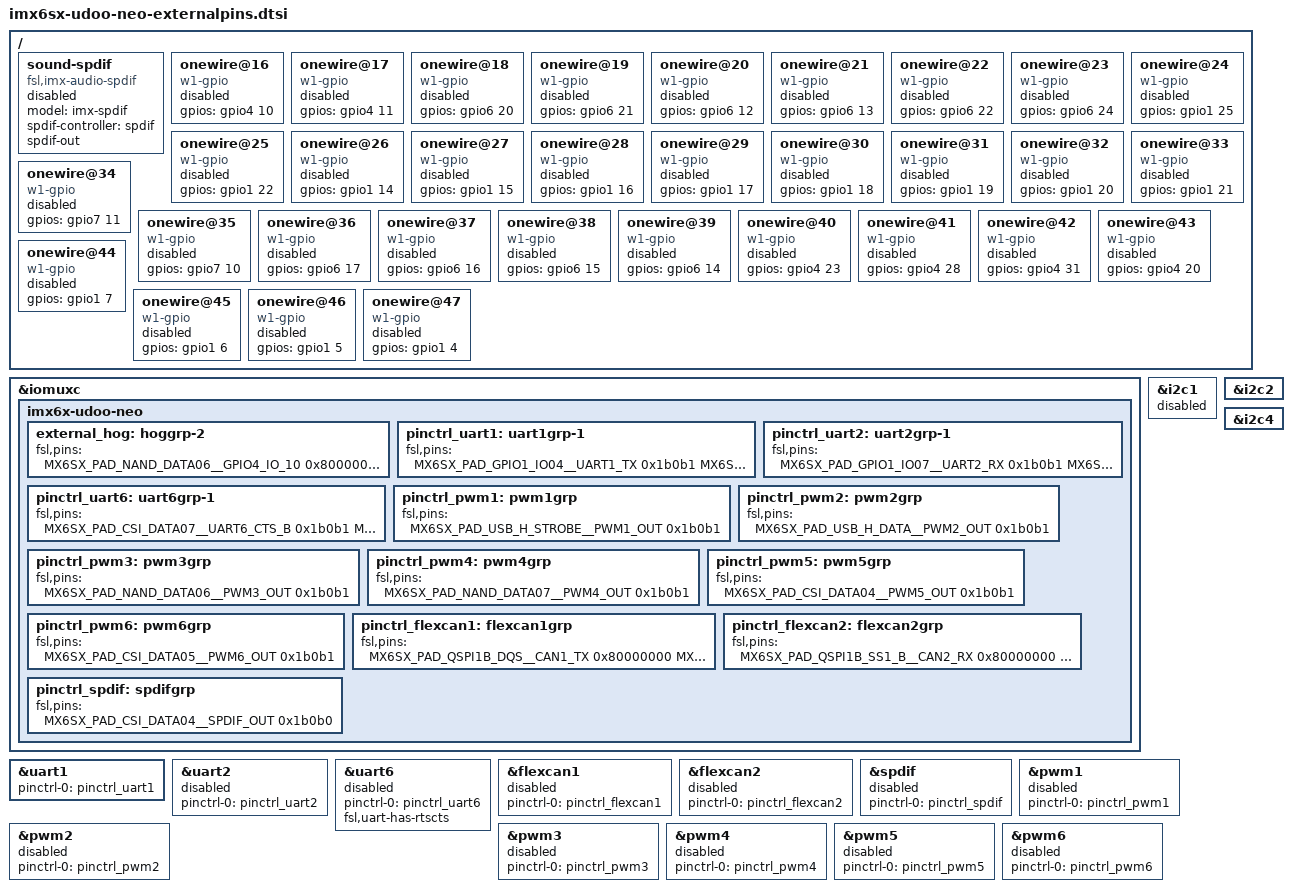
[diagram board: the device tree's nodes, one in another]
/*
 * Author: Francesco Montefoschi <francesco.monte@gmail.com> 
 *
 * This program is free software; you can redistribute it and/or modify
 * it under the terms of the GNU General Public License version 2 as
 * published by the Free Software Foundation.
 *
 */
 

&iomuxc {
    imx6x-udoo-neo {
        // External Pinout GPIOs
        external_hog: hoggrp-2 {
			fsl,pins = <
				MX6SX_PAD_NAND_DATA06__GPIO4_IO_10		0x80000000	// {{external-gpio-16}}
				MX6SX_PAD_NAND_DATA07__GPIO4_IO_11		0x80000000	// {{external-gpio-17}}
				MX6SX_PAD_SD4_DATA6__GPIO6_IO_20		0x80000000	// {{external-gpio-18}}
				MX6SX_PAD_SD4_DATA7__GPIO6_IO_21		0x80000000	// {{external-gpio-19}}
				MX6SX_PAD_SD4_CLK__GPIO6_IO_12			0x80000000	// {{external-gpio-20}}
				MX6SX_PAD_SD4_CMD__GPIO6_IO_13			0x80000000	// {{external-gpio-21}}
				MX6SX_PAD_SD4_RESET_B__GPIO6_IO_22		0x80000000	// {{external-gpio-22}}
				MX6SX_PAD_CSI_PIXCLK__GPIO1_IO_24		0x80000000	// {{external-gpio-23}}	
						
				MX6SX_PAD_CSI_VSYNC__GPIO1_IO_25		0x80000000	// {{external-gpio-24}}
				MX6SX_PAD_CSI_HSYNC__GPIO1_IO_22		0x80000000	// {{external-gpio-25}}
				MX6SX_PAD_CSI_DATA00__GPIO1_IO_14		0x80000000	// {{external-gpio-26}}
				MX6SX_PAD_CSI_DATA01__GPIO1_IO_15		0x80000000	// {{external-gpio-27}}
				MX6SX_PAD_CSI_DATA02__GPIO1_IO_16		0x80000000	// {{external-gpio-28}}
				MX6SX_PAD_CSI_DATA03__GPIO1_IO_17		0x80000000	// {{external-gpio-29}}
				MX6SX_PAD_CSI_DATA04__GPIO1_IO_18		0x80000000	// {{external-gpio-30}}
				MX6SX_PAD_CSI_DATA05__GPIO1_IO_19		0x80000000	// {{external-gpio-31}}
				MX6SX_PAD_CSI_DATA06__GPIO1_IO_20		0x80000000	// {{external-gpio-32}}
				MX6SX_PAD_CSI_DATA07__GPIO1_IO_21		0x80000000	// {{external-gpio-33}}
				
				MX6SX_PAD_USB_H_STROBE__GPIO7_IO_11		0x80000000	// {{external-gpio-34}}
				MX6SX_PAD_USB_H_DATA__GPIO7_IO_10		0x80000000	// {{external-gpio-35}}
				MX6SX_PAD_SD4_DATA3__GPIO6_IO_17		0x80000000	// {{external-gpio-36}}
				MX6SX_PAD_SD4_DATA2__GPIO6_IO_16		0x80000000	// {{external-gpio-37}}
				MX6SX_PAD_SD4_DATA1__GPIO6_IO_15		0x80000000	// {{external-gpio-38}}
				MX6SX_PAD_SD4_DATA0__GPIO6_IO_14		0x80000000	// {{external-gpio-39}}
				
				MX6SX_PAD_QSPI1A_SS1_B__GPIO4_IO_23		0x80000000	// {{external-gpio-40}}
				MX6SX_PAD_QSPI1B_DQS__GPIO4_IO_28		0x80000000	// {{external-gpio-41}}
				MX6SX_PAD_QSPI1B_SS1_B__GPIO4_IO_31		0x80000000	// {{external-gpio-42}}
				MX6SX_PAD_QSPI1A_DQS__GPIO4_IO_20		0x80000000	// {{external-gpio-43}}
				MX6SX_PAD_GPIO1_IO07__GPIO1_IO_7		0x80000000	// {{external-gpio-44}}
				MX6SX_PAD_GPIO1_IO06__GPIO1_IO_6		0x80000000	// {{external-gpio-45}}
				MX6SX_PAD_GPIO1_IO05__GPIO1_IO_5		0x80000000	// {{external-gpio-46}}
				MX6SX_PAD_GPIO1_IO04__GPIO1_IO_4		0x80000000	// {{external-gpio-47}}
			>;
		};
	
		pinctrl_uart1: uart1grp-1 {
			fsl,pins = <
				MX6SX_PAD_GPIO1_IO04__UART1_TX          0x1b0b1
				MX6SX_PAD_GPIO1_IO05__UART1_RX          0x1b0b1
			>;
		};

		pinctrl_uart2: uart2grp-1 {
			fsl,pins = <
				MX6SX_PAD_GPIO1_IO07__UART2_RX          0x1b0b1
				MX6SX_PAD_GPIO1_IO06__UART2_TX          0x1b0b1
			>;
		};

		pinctrl_uart6: uart6grp-1 {
			fsl,pins = <
				MX6SX_PAD_CSI_DATA07__UART6_CTS_B       0x1b0b1
				MX6SX_PAD_CSI_DATA06__UART6_RTS_B       0x1b0b1
				MX6SX_PAD_CSI_DATA05__UART6_TX          0x1b0b1
				MX6SX_PAD_CSI_DATA04__UART6_RX          0x1b0b1
			>;
		};

		pinctrl_pwm1: pwm1grp {
			fsl,pins = <
				MX6SX_PAD_USB_H_STROBE__PWM1_OUT	0x1b0b1
			>;
		};
		
		pinctrl_pwm2: pwm2grp {
			fsl,pins = <
				MX6SX_PAD_USB_H_DATA__PWM2_OUT	0x1b0b1
			>;
		};
		
		pinctrl_pwm3: pwm3grp {
			fsl,pins = <
				MX6SX_PAD_NAND_DATA06__PWM3_OUT	0x1b0b1
			>;
		};
		
		pinctrl_pwm4: pwm4grp {
			fsl,pins = <
				MX6SX_PAD_NAND_DATA07__PWM4_OUT	0x1b0b1
			>;
		};

		pinctrl_pwm5: pwm5grp {
			fsl,pins = <
				MX6SX_PAD_CSI_DATA04__PWM5_OUT	0x1b0b1
			>;
		};

		pinctrl_pwm6: pwm6grp {
			fsl,pins = <
				MX6SX_PAD_CSI_DATA05__PWM6_OUT	0x1b0b1
			>;
		};

		pinctrl_flexcan1: flexcan1grp {
			fsl,pins = <
				MX6SX_PAD_QSPI1B_DQS__CAN1_TX		0x80000000
				MX6SX_PAD_QSPI1A_SS1_B__CAN1_RX		0x80000000
			>;
		};

		pinctrl_flexcan2: flexcan2grp {
			fsl,pins = <
				MX6SX_PAD_QSPI1B_SS1_B__CAN2_RX		0x80000000
				MX6SX_PAD_QSPI1A_DQS__CAN2_TX		0x80000000
			>;
		};

		pinctrl_spdif: spdifgrp {
			fsl,pins = <
				MX6SX_PAD_CSI_DATA04__SPDIF_OUT		0x1b0b0
			>;
		};
	};
 };

&uart1 {
	pinctrl-names = "default";
	pinctrl-0 = <&pinctrl_uart1>;
	status = "okay";
};

&uart2 {
	pinctrl-names = "default";
	pinctrl-0 = <&pinctrl_uart2>;
	status = "disabled";
};

&uart6 {
	pinctrl-names = "default";
	pinctrl-0 = <&pinctrl_uart6>;
	fsl,uart-has-rtscts;
	status = "disabled";
};

&i2c1 {
	status = "disabled";
};

&i2c2 {
	status = "okay";
};

&i2c4 {
	status = "okay";
};

&flexcan1 {
	pinctrl-names = "default";
	pinctrl-0 = <&pinctrl_flexcan1>;
	status = "disabled";
};

&flexcan2 {
	pinctrl-names = "default";
	pinctrl-0 = <&pinctrl_flexcan2>;
	status = "disabled";
};

&spdif {
   pinctrl-names = "default";
   pinctrl-0 = <&pinctrl_spdif>;
   status = "disabled";
};

&pwm1 {
    pinctrl-names = "default";
    pinctrl-0 = <&pinctrl_pwm1>;
    status = "disabled";
};

&pwm2 {
    pinctrl-names = "default";
    pinctrl-0 = <&pinctrl_pwm2>;
    status = "disabled";
};

&pwm3 {
    pinctrl-names = "default";
    pinctrl-0 = <&pinctrl_pwm3>;
    status = "disabled";
};

&pwm4 {
    pinctrl-names = "default";
    pinctrl-0 = <&pinctrl_pwm4>;
    status = "disabled";
};

&pwm5 {
    pinctrl-names = "default";
    pinctrl-0 = <&pinctrl_pwm5>;
    status = "disabled";
};

&pwm6 {
    pinctrl-names = "default";
    pinctrl-0 = <&pinctrl_pwm6>;
    status = "disabled";
};

/ {
	sound-spdif {
		compatible = "fsl,imx-audio-spdif";
		model = "imx-spdif";
		spdif-controller = <&spdif>;
		spdif-out;
		status = "disabled";
	};

	onewire@16 {
		compatible = "w1-gpio";
		gpios = <&gpio4 10 GPIO_ACTIVE_HIGH>;
		status = "disabled";
	};

	onewire@17 {
		compatible = "w1-gpio";
		gpios = <&gpio4 11 GPIO_ACTIVE_HIGH>;
		status = "disabled";
	};

	onewire@18 {
		compatible = "w1-gpio";
		gpios = <&gpio6 20 GPIO_ACTIVE_HIGH>;
		status = "disabled";
	};

	onewire@19 {
		compatible = "w1-gpio";
		gpios = <&gpio6 21 GPIO_ACTIVE_HIGH>;
		status = "disabled";
	};

	onewire@20 {
		compatible = "w1-gpio";
		gpios = <&gpio6 12 GPIO_ACTIVE_HIGH>;
		status = "disabled";
	};

	onewire@21 {
		compatible = "w1-gpio";
		gpios = <&gpio6 13 GPIO_ACTIVE_HIGH>;
		status = "disabled";
	};

	onewire@22 {
		compatible = "w1-gpio";
		gpios = <&gpio6 22 GPIO_ACTIVE_HIGH>;
		status = "disabled";
	};

	onewire@23 {
		compatible = "w1-gpio";
		gpios = <&gpio6 24 GPIO_ACTIVE_HIGH>;
		status = "disabled";
	};

	onewire@24 {
		compatible = "w1-gpio";
		gpios = <&gpio1 25 GPIO_ACTIVE_HIGH>;
		status = "disabled";
	};

	onewire@25 {
		compatible = "w1-gpio";
		gpios = <&gpio1 22 GPIO_ACTIVE_HIGH>;
		status = "disabled";
	};

	onewire@26 {
		compatible = "w1-gpio";
		gpios = <&gpio1 14 GPIO_ACTIVE_HIGH>;
		status = "disabled";
	};

	onewire@27 {
		compatible = "w1-gpio";
		gpios = <&gpio1 15 GPIO_ACTIVE_HIGH>;
		status = "disabled";
	};

	onewire@28 {
		compatible = "w1-gpio";
		gpios = <&gpio1 16 GPIO_ACTIVE_HIGH>;
		status = "disabled";
	};

	onewire@29 {
		compatible = "w1-gpio";
		gpios = <&gpio1 17 GPIO_ACTIVE_HIGH>;
		status = "disabled";
	};

	onewire@30 {
		compatible = "w1-gpio";
		gpios = <&gpio1 18 GPIO_ACTIVE_HIGH>;
		status = "disabled";
	};

	onewire@31 {
		compatible = "w1-gpio";
		gpios = <&gpio1 19 GPIO_ACTIVE_HIGH>;
		status = "disabled";
	};

	onewire@32 {
		compatible = "w1-gpio";
		gpios = <&gpio1 20 GPIO_ACTIVE_HIGH>;
		status = "disabled";
	};

	onewire@33 {
		compatible = "w1-gpio";
		gpios = <&gpio1 21 GPIO_ACTIVE_HIGH>;
		status = "disabled";
	};

	onewire@34 {
		compatible = "w1-gpio";
		gpios = <&gpio7 11 GPIO_ACTIVE_HIGH>;
		status = "disabled";
	};

	onewire@35 {
		compatible = "w1-gpio";
		gpios = <&gpio7 10 GPIO_ACTIVE_HIGH>;
		status = "disabled";
	};

	onewire@36 {
		compatible = "w1-gpio";
		gpios = <&gpio6 17 GPIO_ACTIVE_HIGH>;
		status = "disabled";
	};

	onewire@37 {
		compatible = "w1-gpio";
		gpios = <&gpio6 16 GPIO_ACTIVE_HIGH>;
		status = "disabled";
	};

	onewire@38 {
		compatible = "w1-gpio";
		gpios = <&gpio6 15 GPIO_ACTIVE_HIGH>;
		status = "disabled";
	};

	onewire@39 {
		compatible = "w1-gpio";
		gpios = <&gpio6 14 GPIO_ACTIVE_HIGH>;
		status = "disabled";
	};

	onewire@40 {
		compatible = "w1-gpio";
		gpios = <&gpio4 23 GPIO_ACTIVE_HIGH>;
		status = "disabled";
	};

	onewire@41 {
		compatible = "w1-gpio";
		gpios = <&gpio4 28 GPIO_ACTIVE_HIGH>;
		status = "disabled";
	};

	onewire@42 {
		compatible = "w1-gpio";
		gpios = <&gpio4 31 GPIO_ACTIVE_HIGH>;
		status = "disabled";
	};

	onewire@43 {
		compatible = "w1-gpio";
		gpios = <&gpio4 20 GPIO_ACTIVE_HIGH>;
		status = "disabled";
	};

	onewire@44 {
		compatible = "w1-gpio";
		gpios = <&gpio1 7 GPIO_ACTIVE_HIGH>;
		status = "disabled";
	};

	onewire@45 {
		compatible = "w1-gpio";
		gpios = <&gpio1 6 GPIO_ACTIVE_HIGH>;
		status = "disabled";
	};

	onewire@46 {
		compatible = "w1-gpio";
		gpios = <&gpio1 5 GPIO_ACTIVE_HIGH>;
		status = "disabled";
	};

	onewire@47 {
		compatible = "w1-gpio";
		gpios = <&gpio1 4 GPIO_ACTIVE_HIGH>;
		status = "disabled";
	};

};
